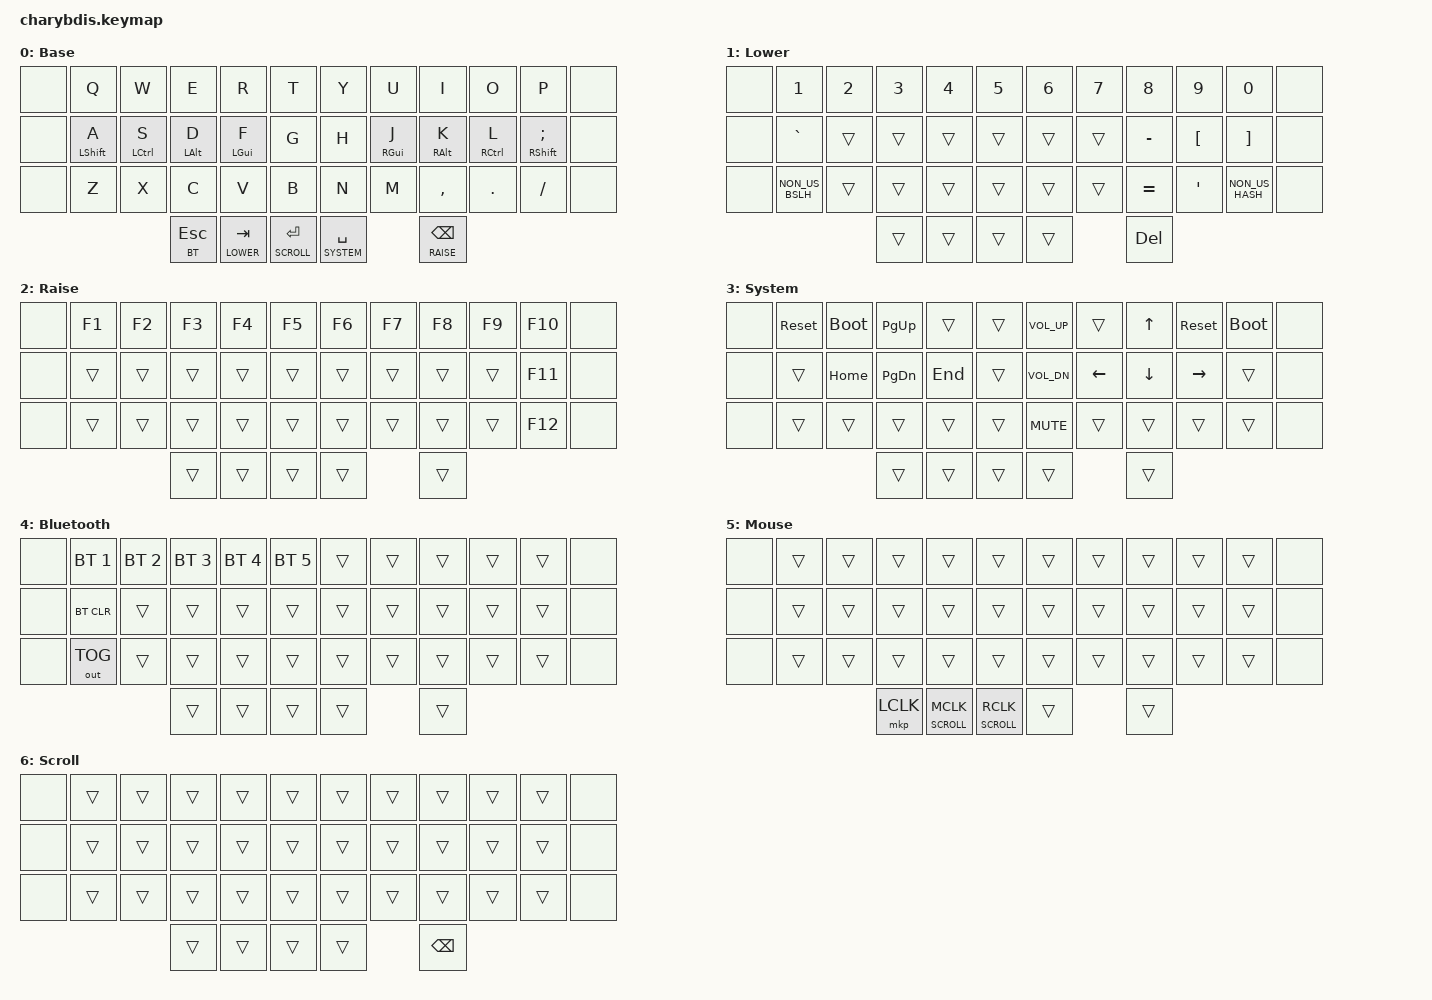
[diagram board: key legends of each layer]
#include <behaviors.dtsi>
#include <dt-bindings/zmk/pointing.h>
#include <dt-bindings/zmk/keys.h>
#include <dt-bindings/zmk/bt.h>
#include <dt-bindings/zmk/outputs.h>
#include <dt-bindings/zmk/keys.h>

#define BASE      0
#define LOWER     1
#define RAISE     2
#define SYSTEM    3
#define BT        4
#define MOUSE     5
#define SCROLL    6

&lt {
    tapping-term-ms = <240>;
    flavor = "balanced";
    quick-tap-ms = <150>;
};

&mt {
    tapping-term-ms = <240>;
    flavor = "balanced";
    quick-tap-ms = <150>;
};



/ {

  behaviors {
      lm: layer_mouse {
          compatible = "zmk,behavior-hold-tap";
          #binding-cells = <2>;
          flavor = "balanced";
          tapping-term-ms = <240>;
          quick-tap-ms = <150>;
          bindings = <&mo>, <&mkp>;
    };
  };

  keymap {
    compatible = "zmk,keymap";

        Base {
            bindings = <
    &none  &kp Q         &kp W        &kp E       &kp R          &kp T                   &kp Y      &kp U       &kp I       &kp O        &kp P           &none
    &none  &mt LSHIFT A  &mt LCTRL S  &mt LALT D  &mt LGUI F     &kp G                   &kp H      &mt RGUI J  &mt RALT K  &mt RCTRL L  &mt RSHFT SEMI  &none
    &none  &kp Z         &kp X        &kp C       &kp V          &kp B                   &kp N      &kp M       &kp COMMA   &kp DOT      &kp FSLH        &none
                                      &lt BT ESC  &lt LOWER TAB  &lt SCROLL ENTER        &lt SYSTEM SPACE       &lt RAISE BSPC
            >;
        };

        Lower {
            bindings = <
    &none  &kp N1           &kp N2  &kp N3  &kp N4  &kp N5            &kp N6  &kp N7  &kp N8     &kp N9    &kp N0            &none
    &none  &kp GRAVE        &trans  &trans  &trans  &trans            &trans  &trans  &kp MINUS  &kp LBKT  &kp RBKT          &none
    &none  &kp NON_US_BSLH  &trans  &trans  &trans  &trans            &trans  &trans  &kp EQUAL  &kp SQT   &kp NON_US_HASH   &none
                                    &trans  &trans  &trans            &trans  &kp DEL
            >;
        };

        Raise {
            bindings = <
    &none  &kp F1  &kp F2  &kp F3  &kp F4  &kp F5         &kp F6  &kp F7  &kp F8  &kp F9  &kp F10  &none
    &none  &trans  &trans  &trans  &trans  &trans         &trans  &trans  &trans  &trans  &kp F11  &none
    &none  &trans  &trans  &trans  &trans  &trans         &trans  &trans  &trans  &trans  &kp F12  &none
                           &trans  &trans  &trans         &trans  &trans
            >;
        };

        System {
            bindings = <
   &none  &sys_reset  &bootloader  &kp PG_UP  &trans   &trans      &kp C_VOL_UP  &trans    &kp UP    &sys_reset  &bootloader  &none
   &none  &trans      &kp HOME     &kp PG_DN  &kp END  &trans      &kp C_VOL_DN  &kp LEFT  &kp DOWN  &kp RIGHT   &trans       &none
   &none  &trans      &trans       &trans     &trans   &trans      &kp C_MUTE  &trans    &trans    &trans        &trans       &none
                                   &trans     &trans   &trans      &trans  &trans
            >;
        };

        Bluetooth {
            bindings = <
   &none  &bt BT_SEL 1  &bt BT_SEL 2  &bt BT_SEL 3  &bt BT_SEL 4  &bt BT_SEL 5      &trans  &trans  &trans  &trans  &trans  &none
   &none  &bt BT_CLR    &trans        &trans        &trans        &trans            &trans  &trans  &trans  &trans  &trans  &none
   &none  &out OUT_TOG  &trans        &trans        &trans        &trans            &trans  &trans  &trans  &trans  &trans  &none
                                      &trans        &trans        &trans            &trans  &trans
            >;
        };

        Mouse {
            bindings = <
   &none  &trans  &trans  &trans     &trans           &trans             &trans  &trans  &trans  &trans  &trans  &none
   &none  &trans  &trans  &trans     &trans           &trans             &trans  &trans  &trans  &trans  &trans  &none
   &none  &trans  &trans  &trans     &trans           &trans             &trans  &trans  &trans  &trans  &trans  &none
                          &mkp LCLK  &lm SCROLL MCLK  &lm SCROLL RCLK    &trans  &trans
            >;
        };

        Scroll {
            bindings = <
   &none  &trans  &trans  &trans    &trans     &trans      &trans  &trans  &trans  &trans  &trans  &none
   &none  &trans  &trans  &trans    &trans     &trans      &trans  &trans  &trans  &trans  &trans  &none
   &none  &trans  &trans  &trans    &trans     &trans      &trans  &trans  &trans  &trans  &trans  &none
                          &trans    &trans     &trans      &trans  &kp BSPC
            >;
        };
    };
};
